# ATSAM4CMP16C_1 register map
Vendor: Atmel; Series: SAM4CM; File version: 0
CPU: CM4 r0p0, selectable endian, no MPU, FPU, 4 interrupt priority bits
Registers are 32-bit, read-write, reset 0x0 unless marked. A register's access mark holds for its fields unless they carry their own. Offsets are from the block's base; [hi:lo] are bit positions; {n}, {i} and the like mark numbered series; 'fields as' and 'values as' point back to an identical list.

## RSTC — Reset Controller
Base 0x400E1400; register names take the prefix RSTC_
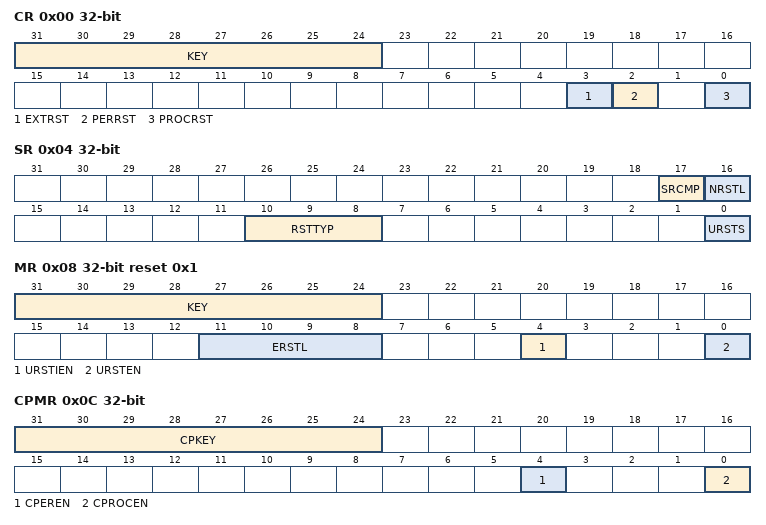
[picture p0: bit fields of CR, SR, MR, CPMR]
0x00 CR wo reset not defined — Control Register
  [31:24] KEY — System Reset Key
    165=PASSWD (Writing any other value in this field aborts the write operation.)
  [3] EXTRST — External Reset
  [2] PERRST — Peripheral Reset
  [0] PROCRST — Processor Reset
0x04 SR ro — Status Register
  [17] SRCMP — Software Reset Command in Progress
  [16] NRSTL — NRST Pin Level
  [10:8] RSTTYP — Reset Type
    0=GENERAL_RST (First power-up reset); 1=BACKUP_RST (Return from Backup Mode); 2=WDT_RST (Watchdog fault occurred); 3=SOFT_RST (Processor reset required by the software); 4=USER_RST (NRST pin detected low)
  [0] URSTS — User Reset Status
0x08 MR reset 0x1 — Mode Register
  [31:24] KEY — Write Access Password
    165=PASSWD (Writing any other value in this field aborts the write operation.Always reads as 0.)
  [11:8] ERSTL — External Reset Length
  [4] URSTIEN — User Reset Interrupt Enable
  [0] URSTEN — User Reset Enable
0x0C CPMR — Coprocessor Mode Register
  [31:24] CPKEY — Coprocessor System Enable Key
    90=PASSWD (Writing any other value in this field aborts the write operation.)
  [4] CPEREN — Coprocessor Peripheral Enable
  [0] CPROCEN — Coprocessor (Second Processor) Enable

## RTT — Real-time Timer
Base 0x400E1430; register names take the prefix RTT_
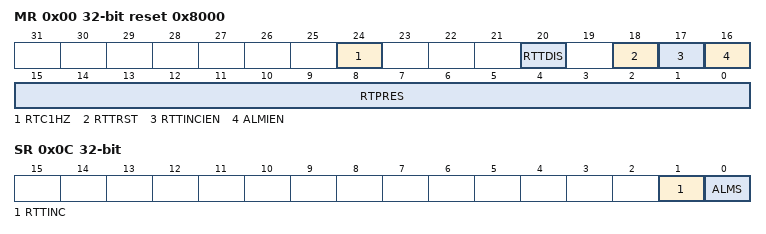
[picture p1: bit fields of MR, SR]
0x00 MR reset 0x8000 — Mode Register
  [24] RTC1HZ — Real-Time Clock 1Hz Clock Selection
  [20] RTTDIS — Real-time Timer Disable
  [18] RTTRST — Real-time Timer Restart
  [17] RTTINCIEN — Real-time Timer Increment Interrupt Enable
  [16] ALMIEN — Alarm Interrupt Enable
  [15:0] RTPRES — Real-time Timer Prescaler Value
0x04 AR reset 0xFFFFFFFF — Alarm Register
  [31:0] ALMV — Alarm Value
0x08 VR ro — Value Register
  [31:0] CRTV — Current Real-time Value
0x0C SR ro — Status Register
  [1] RTTINC — Prescaler Roll-over Status
  [0] ALMS — Real-time Alarm Status

## WDT — Watchdog Timer
Base 0x400E1450; register names take the prefix WDT_
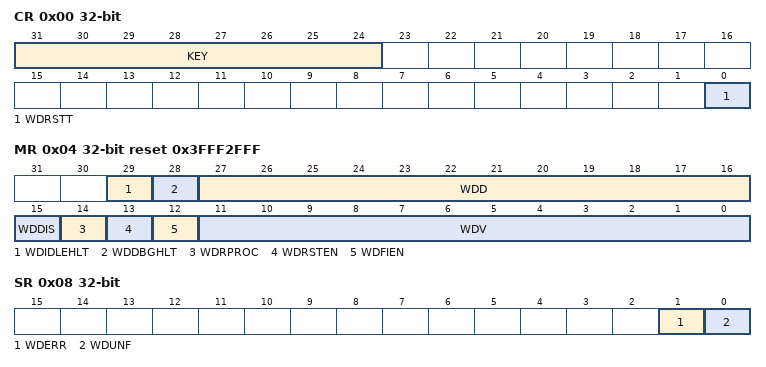
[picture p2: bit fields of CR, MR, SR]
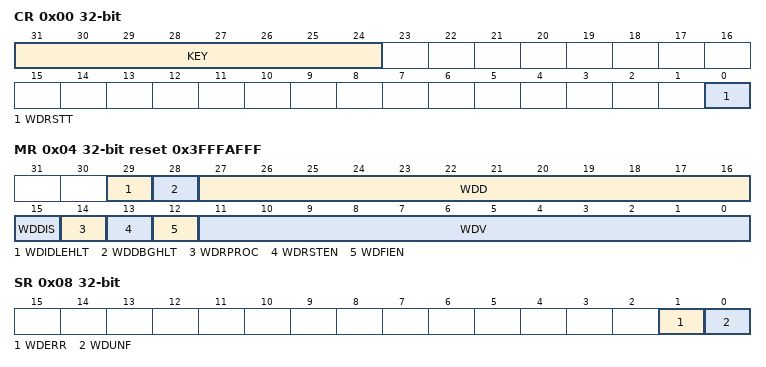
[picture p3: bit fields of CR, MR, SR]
0x00 CR wo reset not defined — Control Register
  [31:24] KEY — Password.
    165=PASSWD (Writing any other value in this field aborts the write operation.)
  [0] WDRSTT — Watchdog Restart
0x04 MR reset 0x3FFF2FFF — Mode Register
  [29] WDIDLEHLT — Watchdog Idle Halt
  [28] WDDBGHLT — Watchdog Debug Halt
  [27:16] WDD — Watchdog Delta Value
  [15] WDDIS — Watchdog Disable
  [14] WDRPROC — Watchdog Reset Processor
  [13] WDRSTEN — Watchdog Reset Enable
  [12] WDFIEN — Watchdog Fault Interrupt Enable
  [11:0] WDV — Watchdog Counter Value
0x08 SR ro — Status Register
  [1] WDERR — Watchdog Error
  [0] WDUNF — Watchdog Underflow

## GPBR — General Purpose Backup Registers
Base 0x400E1490; register names take the prefix GPBR_
{0x0+4i} GPBR[{i}] (i=0..15) reset not defined — General Purpose Backup Register
  [31:0] GPBR_VALUE — Value of GPBR x

## RSWDT — Reinforced Safety Watchdog Timer
Base 0x400E1500; register names take the prefix RSWDT_
0x00 CR wo reset not defined — Control Register
  [31:24] KEY — Password
    196=PASSWD (Writing any other value in this field aborts the write operation.)
  [0] WDRSTT — Watchdog Restart
0x04 MR reset 0x3FFFAFFF — Mode Register
  [29] WDIDLEHLT — Watchdog Idle Halt
  [28] WDDBGHLT — Watchdog Debug Halt
  [27:16] WDD — Watchdog Delta Value
  [15] WDDIS — Watchdog Disable
  [14] WDRPROC — Watchdog Reset Processor
  [13] WDRSTEN — Watchdog Reset Enable
  [12] WDFIEN — Watchdog Fault Interrupt Enable
  [11:0] WDV — Watchdog Counter Value
0x08 SR ro — Status Register
  [1] WDERR — Watchdog Error
  [0] WDUNF — Watchdog Underflow

## PWM — Pulse Width Modulation Controller
Base 0x48008000; register names take the prefix PWM_
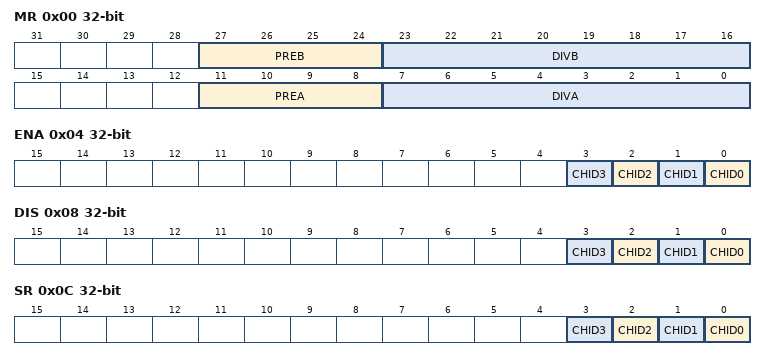
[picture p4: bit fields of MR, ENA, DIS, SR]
0x00 MR — PWM Mode Register
  [27:24] PREB
    0=MCK (Master Clock); 1=MCKDIV2 (Master Clock divided by 2); 2=MCKDIV4 (Master Clock divided by 4); 3=MCKDIV8 (Master Clock divided by 8); 4=MCKDIV16 (Master Clock divided by 16); 5=MCKDIV32 (Master Clock divided by 32); 6=MCKDIV64 (Master Clock divided by 64); 7=MCKDIV128 (Master Clock divided by 128); 8=MCKDIV256 (Master Clock divided by 256); 9=MCKDIV512 (Master Clock divided by 512); 10=MCKDIV1024 (Master Clock divided by 1024)
  [23:16] DIVB — CLKA, CLKB Divide Factor
    0=CLK_OFF (CLKA, CLKB clock is turned off); 1=CLK_DIV1 (CLKA, CLKB clock is clock selected by PREA, PREB)
  [11:8] PREA
    values as PREB
  [7:0] DIVA — CLKA, CLKB Divide Factor
    values as DIVB
0x04 ENA wo reset not defined — PWM Enable Register
  [n] CHID{n} (n=0..3) — Channel ID
0x08 DIS wo reset not defined — PWM Disable Register
  [n] CHID{n} (n=0..3) — Channel ID
0x0C SR ro — PWM Status Register
  [n] CHID{n} (n=0..3) — Channel ID
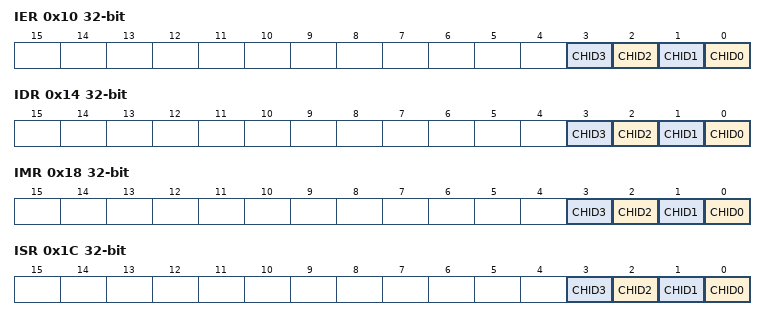
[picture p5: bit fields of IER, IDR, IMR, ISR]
0x10 IER wo reset not defined — PWM Interrupt Enable Register
  [n] CHID{n} (n=0..3) — Channel ID.
0x14 IDR wo reset not defined — PWM Interrupt Disable Register
  [n] CHID{n} (n=0..3) — Channel ID.
0x18 IMR ro — PWM Interrupt Mask Register
  [n] CHID{n} (n=0..3) — Channel ID.
0x1C ISR ro — PWM Interrupt Status Register
  [n] CHID{n} (n=0..3) — Channel ID
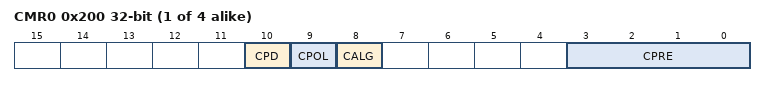
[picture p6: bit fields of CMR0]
{0x200+0x20*i} CMR{i} (i=0..3) — PWM Channel Mode Register (ch_num = {i})
  [10] CPD — Channel Update Period
  [9] CPOL — Channel Polarity
  [8] CALG — Channel Alignment
  [3:0] CPRE — Channel Pre-scaler
    0=MCK (Master Clock); 1=MCKDIV2 (Master Clock divided by 2); 2=MCKDIV4 (Master Clock divided by 4); 3=MCKDIV8 (Master Clock divided by 8); 4=MCKDIV16 (Master Clock divided by 16); 5=MCKDIV32 (Master Clock divided by 32); 6=MCKDIV64 (Master Clock divided by 64); 7=MCKDIV128 (Master Clock divided by 128); 8=MCKDIV256 (Master Clock divided by 256); 9=MCKDIV512 (Master Clock divided by 512); 10=MCKDIV1024 (Master Clock divided by 1024); 11=CLKA (Clock A); 12=CLKB (Clock B)
{0x204+0x20*i} CDTY{i} (i=0..3) — PWM Channel Duty Cycle Register (ch_num = {i})
  [31:0] CDTY — Channel Duty Cycle
{0x208+0x20*i} CPRD{i} (i=0..3) — PWM Channel Period Register (ch_num = {i})
  [31:0] CPRD — Channel Period
{0x20C+0x20*i} CCNT{i} ro (i=0..3) — PWM Channel Counter Register (ch_num = {i})
  [31:0] CNT — Channel Counter Register
{0x210+0x20*i} CUPD{i} wo reset not defined (i=0..3) — PWM Channel Update Register (ch_num = {i})
  [31:0] CUPD

## Notices in the file
SAM Software Package License
Copyright (c) 2015, Atmel Corporation
All rights reserved.
Redistribution and use in source and binary forms, with or without
modification, are permitted provided that the following condition is met:
- Redistributions of source code must retain the above copyright notice,
this list of conditions and the disclaimer below.
Atmel's name may not be used to endorse or promote products derived from
this software without specific prior written permission.
DISCLAIMER:  THIS SOFTWARE IS PROVIDED BY ATMEL "AS IS" AND ANY EXPRESS OR
IMPLIED WARRANTIES, INCLUDING, BUT NOT LIMITED TO, THE IMPLIED WARRANTIES OF
MERCHANTABILITY, FITNESS FOR A PARTICULAR PURPOSE AND NON-INFRINGEMENT ARE
DISCLAIMED. IN NO EVENT SHALL ATMEL BE LIABLE FOR ANY DIRECT, INDIRECT,
INCIDENTAL, SPECIAL, EXEMPLARY, OR CONSEQUENTIAL DAMAGES (INCLUDING, BUT NOT
LIMITED TO, PROCUREMENT OF SUBSTITUTE GOODS OR SERVICES; LOSS OF USE, DATA,
OR PROFITS; OR BUSINESS INTERRUPTION) HOWEVER CAUSED AND ON ANY THEORY OF
LIABILITY, WHETHER IN CONTRACT, STRICT LIABILITY, OR TORT (INCLUDING
NEGLIGENCE OR OTHERWISE) ARISING IN ANY WAY OUT OF THE USE OF THIS SOFTWARE,
EVEN IF ADVISED OF THE POSSIBILITY OF SUCH DAMAGE.
